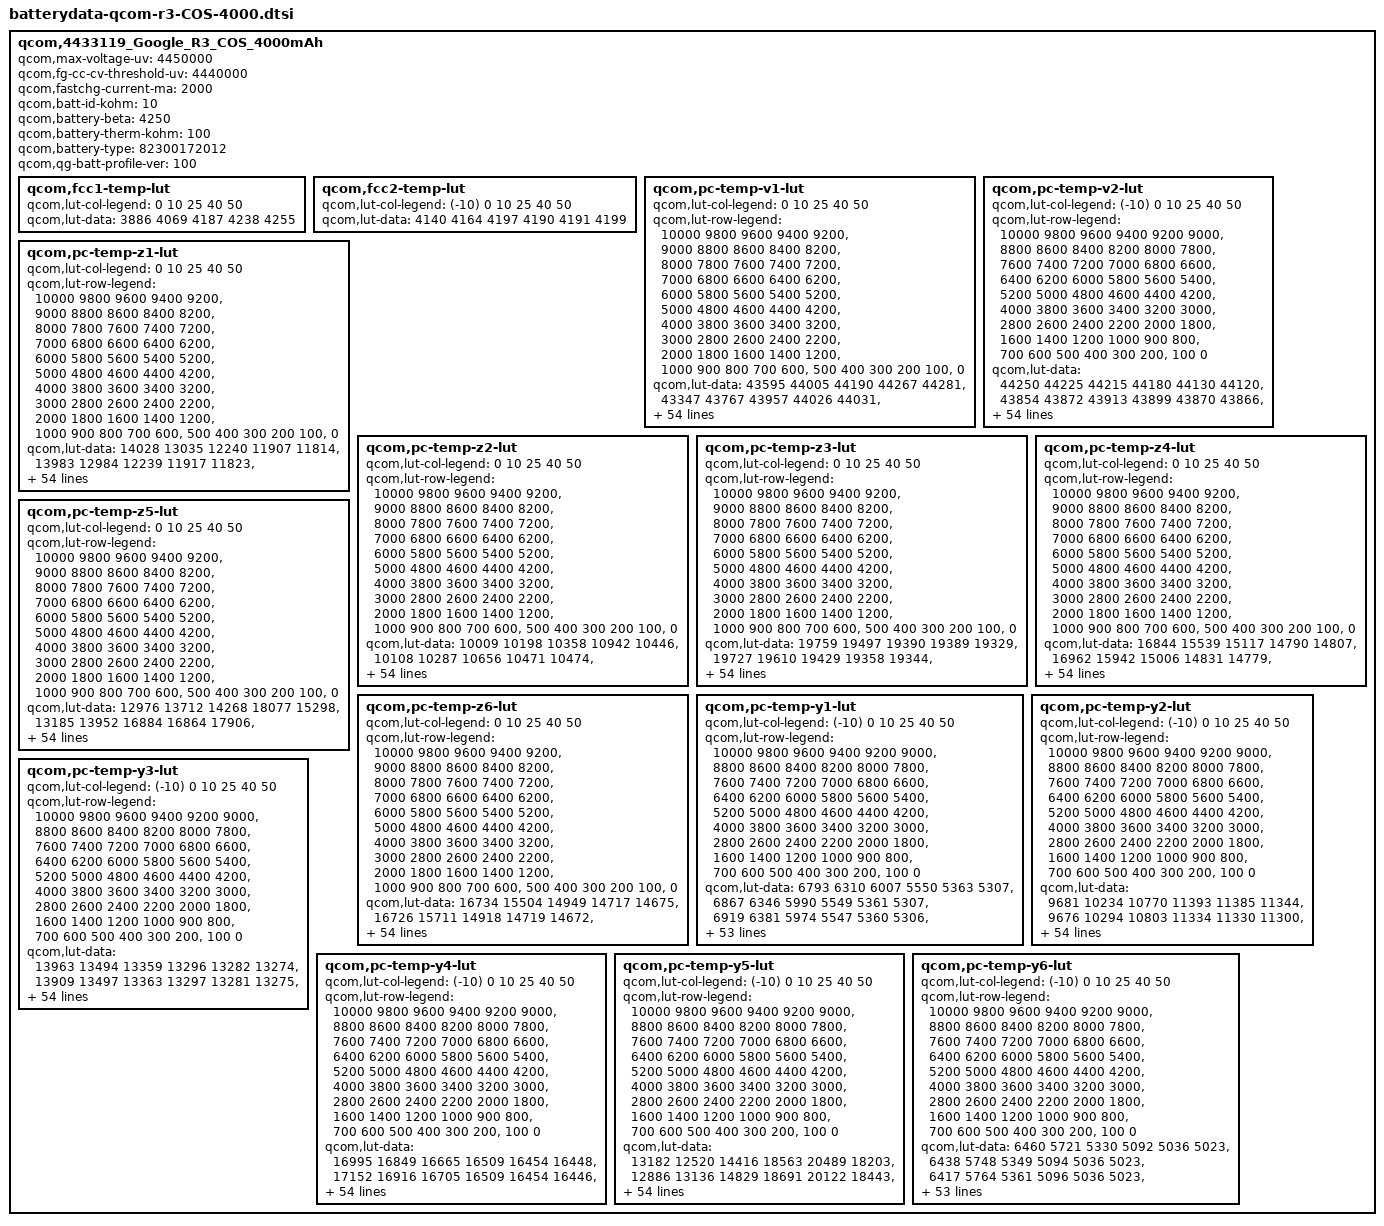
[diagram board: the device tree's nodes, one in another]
// SPDX-License-Identifier: GPL-2.0
qcom,4433119_Google_R3_COS_4000mAh {
	/* 4433119_Google_R3_COS_4000mAh_Feb5th2020 */
	qcom,max-voltage-uv = <4450000>;
	qcom,fg-cc-cv-threshold-uv = <4440000>;
	qcom,fastchg-current-ma = <2000>;
	qcom,batt-id-kohm = <10>;
	qcom,battery-beta = <4250>;
	qcom,battery-therm-kohm = <100>;
	qcom,battery-type = "82300172012";
	qcom,qg-batt-profile-ver = <100>;

	qcom,fcc1-temp-lut {
		qcom,lut-col-legend = <0 10 25 40 50>;
		qcom,lut-data = <3886 4069 4187 4238 4255>;
	};

	qcom,fcc2-temp-lut {
		qcom,lut-col-legend = <(-10) 0 10 25 40 50>;
		qcom,lut-data = <4140 4164 4197 4190 4191 4199>;
	};

	qcom,pc-temp-v1-lut {
		qcom,lut-col-legend = <0 10 25 40 50>;
		qcom,lut-row-legend = <10000 9800 9600 9400 9200>,
			<9000 8800 8600 8400 8200>,
			<8000 7800 7600 7400 7200>,
			<7000 6800 6600 6400 6200>,
			<6000 5800 5600 5400 5200>,
			<5000 4800 4600 4400 4200>,
			<4000 3800 3600 3400 3200>,
			<3000 2800 2600 2400 2200>,
			<2000 1800 1600 1400 1200>,
			<1000 900 800 700 600>,
			<500 400 300 200 100>,
			<0>;
		qcom,lut-data = <43595 44005 44190 44267 44281>,
			<43347 43767 43957 44026 44031>,
			<43101 43540 43748 43802 43812>,
			<42858 43315 43511 43591 43597>,
			<42618 43080 43286 43368 43378>,
			<42378 42836 43053 43136 43156>,
			<42144 42592 42813 42900 42923>,
			<41914 42349 42569 42659 42681>,
			<41689 42106 42322 42415 42438>,
			<41469 41870 42074 42168 42191>,
			<41255 41638 41833 41924 41947>,
			<41046 41412 41598 41685 41708>,
			<40842 41189 41369 41452 41474>,
			<40644 40974 41146 41222 41243>,
			<40451 40765 40928 40998 41016>,
			<40264 40564 40719 40782 40798>,
			<40085 40370 40515 40573 40588>,
			<39921 40182 40321 40373 40385>,
			<39770 40003 40135 40185 40196>,
			<39627 39837 39956 40004 40014>,
			<39491 39679 39793 39824 39832>,
			<39361 39524 39626 39649 39652>,
			<39236 39374 39392 39451 39458>,
			<39115 39213 39090 39199 39220>,
			<39000 39012 38890 38978 38998>,
			<38891 38806 38785 38837 38847>,
			<38788 38656 38701 38725 38725>,
			<38690 38535 38612 38617 38613>,
			<38597 38446 38527 38515 38509>,
			<38508 38385 38447 38422 38414>,
			<38433 38337 38373 38337 38326>,
			<38363 38293 38304 38262 38246>,
			<38306 38254 38243 38195 38175>,
			<38259 38218 38187 38135 38110>,
			<38220 38186 38140 38080 38047>,
			<38181 38153 38099 38031 37988>,
			<38147 38118 38055 37977 37925>,
			<38107 38079 38010 37920 37856>,
			<38054 38025 37954 37853 37780>,
			<37985 37934 37869 37768 37693>,
			<37897 37821 37757 37664 37592>,
			<37763 37703 37633 37547 37478>,
			<37624 37569 37492 37411 37342>,
			<37492 37405 37333 37255 37187>,
			<37360 37258 37180 37101 37036>,
			<37246 37156 37088 37012 36954>,
			<37203 37128 37062 36991 36931>,
			<37162 37106 37047 36977 36915>,
			<37124 37077 37030 36960 36901>,
			<37072 37036 36993 36923 36858>,
			<36898 36858 36800 36720 36634>,
			<36470 36434 36383 36297 36201>,
			<35892 35855 35812 35731 35633>,
			<35104 35063 35035 34962 34862>,
			<33798 33784 33845 33793 33676>,
			<30000 30000 30000 30000 30000>;
	};

	qcom,pc-temp-v2-lut {
		qcom,lut-col-legend = <(-10) 0 10 25 40 50>;
		qcom,lut-row-legend = <10000 9800 9600 9400 9200 9000>,
			<8800 8600 8400 8200 8000 7800>,
			<7600 7400 7200 7000 6800 6600>,
			<6400 6200 6000 5800 5600 5400>,
			<5200 5000 4800 4600 4400 4200>,
			<4000 3800 3600 3400 3200 3000>,
			<2800 2600 2400 2200 2000 1800>,
			<1600 1400 1200 1000 900 800>,
			<700 600 500 400 300 200>,
			<100 0>;
		qcom,lut-data = <44250 44225 44215 44180 44130 44120>,
			<43854 43872 43913 43899 43870 43866>,
			<43497 43554 43634 43636 43621 43622>,
			<43184 43278 43380 43394 43386 43389>,
			<42908 43038 43150 43170 43164 43168>,
			<42649 42795 42913 42940 42935 42940>,
			<42410 42538 42663 42698 42696 42702>,
			<42172 42281 42412 42454 42454 42461>,
			<41906 42034 42164 42211 42213 42220>,
			<41625 41792 41919 41969 41972 41979>,
			<41376 41547 41679 41731 41734 41742>,
			<41163 41295 41443 41496 41499 41509>,
			<40954 41060 41215 41267 41270 41280>,
			<40735 40865 40997 41042 41044 41055>,
			<40509 40680 40785 40823 40825 40835>,
			<40253 40457 40581 40610 40614 40623>,
			<39958 40199 40382 40404 40411 40417>,
			<39698 39950 40166 40207 40215 40220>,
			<39500 39718 39922 40026 40029 40033>,
			<39321 39496 39680 39839 39843 39849>,
			<39137 39288 39450 39621 39651 39664>,
			<38954 39091 39231 39390 39452 39474>,
			<38764 38909 39039 39171 39237 39259>,
			<38547 38742 38866 38959 38998 39014>,
			<38364 38574 38711 38780 38803 38818>,
			<38260 38378 38572 38640 38665 38678>,
			<38183 38196 38445 38519 38549 38560>,
			<38111 38097 38326 38408 38440 38450>,
			<38044 38034 38213 38309 38341 38351>,
			<37980 37980 38104 38217 38250 38257>,
			<37919 37930 37994 38132 38167 38171>,
			<37857 37883 37910 38054 38091 38091>,
			<37795 37836 37858 37984 38023 38022>,
			<37731 37788 37816 37919 37958 37955>,
			<37667 37738 37774 37852 37886 37878>,
			<37603 37686 37735 37783 37810 37793>,
			<37537 37629 37691 37715 37725 37699>,
			<37470 37568 37639 37649 37627 37586>,
			<37401 37500 37576 37580 37527 37477>,
			<37332 37421 37495 37503 37442 37387>,
			<37262 37328 37396 37416 37358 37302>,
			<37193 37217 37286 37314 37263 37210>,
			<37124 37093 37153 37189 37145 37091>,
			<37045 36977 36998 37048 37015 36958>,
			<36956 36870 36857 36896 36867 36817>,
			<36849 36780 36758 36848 36833 36785>,
			<36791 36741 36724 36830 36824 36776>,
			<36720 36704 36691 36813 36809 36763>,
			<36650 36664 36644 36786 36786 36739>,
			<36543 36598 36569 36723 36726 36672>,
			<36383 36439 36389 36494 36486 36401>,
			<36111 36051 35987 36019 36013 35922>,
			<35674 35418 35358 35384 35388 35292>,
			<34955 34428 34451 34506 34528 34423>,
			<33712 32850 33003 33173 33262 33124>,
			<30996 29589 29511 29509 29575 29508>;
	};

	qcom,pc-temp-z1-lut {
		qcom,lut-col-legend = <0 10 25 40 50>;
		qcom,lut-row-legend = <10000 9800 9600 9400 9200>,
			<9000 8800 8600 8400 8200>,
			<8000 7800 7600 7400 7200>,
			<7000 6800 6600 6400 6200>,
			<6000 5800 5600 5400 5200>,
			<5000 4800 4600 4400 4200>,
			<4000 3800 3600 3400 3200>,
			<3000 2800 2600 2400 2200>,
			<2000 1800 1600 1400 1200>,
			<1000 900 800 700 600>,
			<500 400 300 200 100>,
			<0>;
		qcom,lut-data = <14028 13035 12240 11907 11814>,
			<13983 12984 12239 11917 11823>,
			<13967 12988 12232 11912 11821>,
			<13958 12998 12222 11903 11815>,
			<13957 12996 12216 11896 11812>,
			<13970 12991 12210 11890 11810>,
			<13985 12985 12200 11886 11808>,
			<13987 12976 12192 11883 11807>,
			<13971 12964 12186 11880 11806>,
			<13961 12949 12181 11878 11805>,
			<13918 12932 12181 11876 11804>,
			<13864 12921 12185 11875 11803>,
			<13846 12913 12186 11874 11803>,
			<13819 12909 12181 11873 11802>,
			<13796 12911 12175 11873 11802>,
			<13762 12914 12174 11873 11802>,
			<13718 12915 12173 11874 11803>,
			<13703 12912 12174 11874 11803>,
			<13702 12910 12181 11875 11804>,
			<13702 12918 12186 11876 11806>,
			<13698 12933 12188 11878 11807>,
			<13693 12945 12189 11879 11807>,
			<13696 12958 12191 11881 11808>,
			<13711 12965 12194 11883 11810>,
			<13726 12960 12197 11886 11813>,
			<13729 12954 12203 11889 11816>,
			<13728 12954 12209 11893 11819>,
			<13729 12961 12214 11897 11821>,
			<13735 12970 12220 11901 11824>,
			<13745 12986 12225 11904 11827>,
			<13763 13003 12232 11907 11829>,
			<13803 13012 12236 11910 11831>,
			<13826 13021 12239 11914 11834>,
			<13818 13026 12243 11917 11836>,
			<13803 13037 12249 11920 11839>,
			<13794 13050 12260 11925 11842>,
			<13790 13056 12268 11929 11845>,
			<13793 13060 12276 11933 11848>,
			<13807 13066 12283 11937 11852>,
			<13830 13085 12288 11941 11855>,
			<13847 13103 12292 11946 11857>,
			<13861 13112 12298 11949 11860>,
			<13866 13121 12306 11952 11863>,
			<13850 13131 12312 11955 11865>,
			<13851 13131 12319 11959 11867>,
			<13941 13123 12323 11964 11869>,
			<13890 13128 12319 11964 11868>,
			<13883 13157 12328 11965 11869>,
			<13860 13139 12334 11967 11870>,
			<13916 13146 12332 11971 11874>,
			<13922 13151 12347 11976 11878>,
			<13891 13186 12360 11982 11884>,
			<13965 13208 12371 11994 11892>,
			<13967 13229 12405 12008 11902>,
			<13967 13229 12405 12008 11902>,
			<13967 13229 12405 12008 11902>;
	};

	qcom,pc-temp-z2-lut {
		qcom,lut-col-legend = <0 10 25 40 50>;
		qcom,lut-row-legend = <10000 9800 9600 9400 9200>,
			<9000 8800 8600 8400 8200>,
			<8000 7800 7600 7400 7200>,
			<7000 6800 6600 6400 6200>,
			<6000 5800 5600 5400 5200>,
			<5000 4800 4600 4400 4200>,
			<4000 3800 3600 3400 3200>,
			<3000 2800 2600 2400 2200>,
			<2000 1800 1600 1400 1200>,
			<1000 900 800 700 600>,
			<500 400 300 200 100>,
			<0>;
		qcom,lut-data = <10009 10198 10358 10942 10446>,
			<10108 10287 10656 10471 10474>,
			<10101 10273 11089 10519 10509>,
			<10080 10251 10496 10590 10515>,
			<10072 10229 10444 10578 10457>,
			<10071 10202 10430 10557 10387>,
			<10071 10189 10560 10514 10366>,
			<10071 10185 10673 10442 10355>,
			<10070 10182 10563 10415 10353>,
			<10067 10173 10369 10407 10362>,
			<10061 10156 10339 10404 10374>,
			<10052 10145 10362 10395 10384>,
			<10044 10139 10394 10390 10394>,
			<10031 10136 10550 10403 10406>,
			<10019 10135 10729 10425 10420>,
			<10009 10136 10784 10436 10433>,
			<10000 10141 10818 10441 10444>,
			<9995 10152 10809 10447 10456>,
			<9992 10168 10628 10467 10477>,
			<9990 10192 10501 10490 10502>,
			<9989 10224 10519 10497 10517>,
			<9987 10253 10542 10500 10530>,
			<9987 10280 10551 10500 10542>,
			<9990 10306 10556 10492 10567>,
			<9995 10338 10554 10486 10588>,
			<10001 10367 10507 10561 10569>,
			<10012 10373 10464 10685 10519>,
			<10026 10371 10497 10677 10478>,
			<10047 10370 10563 10566 10407>,
			<10071 10378 10575 10509 10374>,
			<10090 10386 10560 10500 10378>,
			<10108 10390 10551 10496 10386>,
			<10120 10391 10561 10502 10411>,
			<10127 10394 10579 10516 10466>,
			<10131 10402 10602 10537 10522>,
			<10134 10413 10637 10579 10586>,
			<10130 10420 10657 10630 10635>,
			<10128 10427 10663 10702 10663>,
			<10134 10438 10671 10765 10686>,
			<10142 10467 10700 10793 10707>,
			<10154 10490 10739 10811 10726>,
			<10179 10486 10745 10815 10743>,
			<10175 10477 10743 10804 10757>,
			<9868 10484 10742 10808 10759>,
			<9608 10548 10759 10817 10756>,
			<9548 10647 10815 10794 10794>,
			<9578 10593 10799 10791 10780>,
			<9565 10546 10776 10785 10782>,
			<9596 10591 10771 10803 10821>,
			<9648 10624 10789 10884 10958>,
			<9609 10551 10859 10843 10768>,
			<9499 10497 10844 10729 10584>,
			<9431 10306 10803 10645 10503>,
			<9301 10127 10753 10558 10480>,
			<9301 10127 10753 10558 10480>,
			<9301 10127 10753 10558 10480>;
	};

	qcom,pc-temp-z3-lut {
		qcom,lut-col-legend = <0 10 25 40 50>;
		qcom,lut-row-legend = <10000 9800 9600 9400 9200>,
			<9000 8800 8600 8400 8200>,
			<8000 7800 7600 7400 7200>,
			<7000 6800 6600 6400 6200>,
			<6000 5800 5600 5400 5200>,
			<5000 4800 4600 4400 4200>,
			<4000 3800 3600 3400 3200>,
			<3000 2800 2600 2400 2200>,
			<2000 1800 1600 1400 1200>,
			<1000 900 800 700 600>,
			<500 400 300 200 100>,
			<0>;
		qcom,lut-data = <19759 19497 19390 19389 19329>,
			<19727 19610 19429 19358 19344>,
			<19708 19640 19436 19369 19343>,
			<19693 19652 19477 19392 19365>,
			<19689 19653 19480 19400 19367>,
			<19695 19649 19482 19403 19367>,
			<19704 19645 19487 19401 19367>,
			<19711 19638 19490 19394 19367>,
			<19718 19631 19480 19388 19366>,
			<19723 19623 19462 19384 19364>,
			<19726 19612 19450 19379 19361>,
			<19728 19603 19440 19372 19355>,
			<19729 19595 19436 19365 19350>,
			<19729 19588 19441 19363 19348>,
			<19727 19578 19448 19362 19347>,
			<19723 19566 19446 19360 19346>,
			<19717 19557 19442 19359 19344>,
			<19709 19550 19436 19358 19341>,
			<19699 19544 19424 19356 19338>,
			<19689 19538 19415 19355 19336>,
			<19682 19534 19414 19356 19336>,
			<19675 19532 19414 19358 19338>,
			<19674 19531 19418 19359 19339>,
			<19677 19530 19431 19353 19334>,
			<19682 19541 19435 19349 19330>,
			<19686 19558 19422 19357 19342>,
			<19691 19560 19409 19371 19367>,
			<19695 19558 19411 19380 19371>,
			<19701 19554 19416 19386 19368>,
			<19705 19550 19421 19388 19364>,
			<19706 19545 19430 19384 19359>,
			<19705 19540 19435 19377 19353>,
			<19702 19536 19433 19372 19349>,
			<19697 19532 19430 19367 19344>,
			<19690 19529 19427 19363 19341>,
			<19682 19526 19422 19359 19338>,
			<19672 19523 19418 19357 19337>,
			<19660 19519 19416 19357 19337>,
			<19646 19516 19414 19358 19337>,
			<19631 19514 19411 19357 19337>,
			<19622 19511 19408 19355 19337>,
			<19619 19507 19406 19353 19336>,
			<19603 19500 19405 19351 19334>,
			<19458 19494 19403 19351 19335>,
			<19310 19471 19396 19350 19337>,
			<19271 19440 19380 19339 19323>,
			<19269 19404 19378 19337 19322>,
			<19269 19347 19365 19333 19321>,
			<19269 19334 19357 19332 19315>,
			<19267 19322 19359 19328 19308>,
			<19268 19333 19350 19333 19325>,
			<19271 19333 19346 19340 19336>,
			<19273 19335 19340 19344 19337>,
			<19292 19337 19333 19343 19329>,
			<19292 19337 19333 19343 19329>,
			<19292 19337 19333 19343 19329>;
	};

	qcom,pc-temp-z4-lut {
		qcom,lut-col-legend = <0 10 25 40 50>;
		qcom,lut-row-legend = <10000 9800 9600 9400 9200>,
			<9000 8800 8600 8400 8200>,
			<8000 7800 7600 7400 7200>,
			<7000 6800 6600 6400 6200>,
			<6000 5800 5600 5400 5200>,
			<5000 4800 4600 4400 4200>,
			<4000 3800 3600 3400 3200>,
			<3000 2800 2600 2400 2200>,
			<2000 1800 1600 1400 1200>,
			<1000 900 800 700 600>,
			<500 400 300 200 100>,
			<0>;
		qcom,lut-data = <16844 15539 15117 14790 14807>,
			<16962 15942 15006 14831 14779>,
			<16817 15764 14981 14784 14746>,
			<16455 15492 15054 14853 14796>,
			<16163 15332 14958 14823 14790>,
			<15949 15213 14880 14783 14766>,
			<15766 15119 14815 14760 14747>,
			<15619 15042 14773 14743 14729>,
			<15495 14980 14757 14729 14716>,
			<15393 14931 14745 14715 14706>,
			<15306 14890 14739 14706 14698>,
			<15233 14854 14732 14701 14693>,
			<15173 14818 14723 14697 14688>,
			<15121 14792 14701 14691 14682>,
			<15078 14782 14680 14684 14674>,
			<15043 14777 14675 14678 14668>,
			<15013 14771 14672 14673 14664>,
			<14985 14764 14671 14669 14661>,
			<14958 14757 14682 14665 14658>,
			<14936 14749 14690 14663 14656>,
			<14921 14740 14691 14664 14657>,
			<14909 14738 14692 14669 14663>,
			<14896 14738 14721 14683 14677>,
			<14883 14739 14817 14756 14734>,
			<14870 14767 14856 14812 14786>,
			<14858 14813 14847 14795 14769>,
			<14847 14834 14833 14760 14725>,
			<14838 14850 14813 14732 14703>,
			<14831 14857 14787 14708 14692>,
			<14825 14846 14764 14693 14684>,
			<14823 14828 14740 14687 14677>,
			<14821 14814 14726 14683 14672>,
			<14820 14801 14721 14680 14667>,
			<14816 14789 14718 14678 14663>,
			<14810 14777 14717 14678 14663>,
			<14804 14767 14717 14679 14666>,
			<14796 14758 14717 14681 14670>,
			<14788 14750 14718 14685 14677>,
			<14779 14748 14719 14688 14683>,
			<14770 14750 14721 14692 14684>,
			<14762 14752 14725 14695 14683>,
			<14756 14747 14723 14694 14682>,
			<14760 14734 14715 14687 14676>,
			<14885 14726 14708 14685 14676>,
			<14949 14706 14697 14685 14679>,
			<14961 14680 14664 14660 14659>,
			<14954 14709 14655 14652 14650>,
			<14949 14762 14656 14641 14636>,
			<14946 14770 14653 14628 14628>,
			<14937 14776 14648 14629 14630>,
			<14933 14768 14671 14643 14633>,
			<14959 14787 14681 14643 14632>,
			<14983 14798 14689 14639 14632>,
			<15013 14819 14699 14640 14638>,
			<15013 14819 14699 14640 14638>,
			<15013 14819 14699 14640 14638>;
	};

	qcom,pc-temp-z5-lut {
		qcom,lut-col-legend = <0 10 25 40 50>;
		qcom,lut-row-legend = <10000 9800 9600 9400 9200>,
			<9000 8800 8600 8400 8200>,
			<8000 7800 7600 7400 7200>,
			<7000 6800 6600 6400 6200>,
			<6000 5800 5600 5400 5200>,
			<5000 4800 4600 4400 4200>,
			<4000 3800 3600 3400 3200>,
			<3000 2800 2600 2400 2200>,
			<2000 1800 1600 1400 1200>,
			<1000 900 800 700 600>,
			<500 400 300 200 100>,
			<0>;
		qcom,lut-data = <12976 13712 14268 18077 15298>,
			<13185 13952 16884 16864 17906>,
			<13555 14248 16307 19571 18865>,
			<14096 14742 16975 18252 19328>,
			<14635 15126 17533 19234 19286>,
			<15174 15481 18230 20301 19299>,
			<15720 15891 19545 20197 19472>,
			<16255 16453 20570 19777 19982>,
			<16787 17054 20811 19763 20546>,
			<17273 17550 20851 20491 21275>,
			<17706 18025 20772 20939 21723>,
			<18101 18707 20697 20438 21468>,
			<18480 20060 20745 19832 21031>,
			<18880 21133 23966 20001 21213>,
			<19163 21295 27961 20762 22364>,
			<19310 21367 29218 21538 23324>,
			<19412 21525 29991 22335 23978>,
			<19466 21982 30046 23141 24478>,
			<19450 22655 27297 23900 24795>,
			<19425 23665 25562 24757 25010>,
			<19443 25119 26623 26188 25319>,
			<19541 26704 28445 28219 26865>,
			<19823 28426 32117 28530 27381>,
			<20743 31011 39033 24063 22340>,
			<22079 39631 41155 20072 17295>,
			<23581 49982 32006 19364 17815>,
			<25484 50890 23232 18954 19595>,
			<27511 47262 22241 19509 20975>,
			<30286 43513 21901 22295 22134>,
			<33142 40398 22529 24707 23156>,
			<34952 37759 25805 26214 24090>,
			<36503 36163 29256 27538 25038>,
			<37208 34823 32267 28961 26145>,
			<36842 34368 34607 30263 27396>,
			<36095 34602 35384 30894 28532>,
			<35412 34964 35868 31248 29760>,
			<34345 35262 35956 31443 30309>,
			<33274 35612 35497 31636 29860>,
			<32344 36165 34796 31773 29037>,
			<31409 37855 33441 30782 28037>,
			<31324 39251 31824 28279 26649>,
			<33708 38151 31700 27136 25688>,
			<34203 35924 32204 26599 25029>,
			<22454 35428 31573 26088 24602>,
			<13540 33715 30949 25422 24161>,
			<11472 29995 32564 25808 21848>,
			<11396 22046 32105 25722 22502>,
			<11378 14305 26237 26171 25462>,
			<11335 13409 23342 30243 26130>,
			<11287 12996 24703 28550 22034>,
			<11313 13553 19901 22988 25021>,
			<11382 13212 17308 22778 26971>,
			<11308 12944 15958 23549 25921>,
			<11404 12612 14737 22098 20263>,
			<11404 12612 14737 22098 20263>,
			<11404 12612 14737 22098 20263>;
	};

	qcom,pc-temp-z6-lut {
		qcom,lut-col-legend = <0 10 25 40 50>;
		qcom,lut-row-legend = <10000 9800 9600 9400 9200>,
			<9000 8800 8600 8400 8200>,
			<8000 7800 7600 7400 7200>,
			<7000 6800 6600 6400 6200>,
			<6000 5800 5600 5400 5200>,
			<5000 4800 4600 4400 4200>,
			<4000 3800 3600 3400 3200>,
			<3000 2800 2600 2400 2200>,
			<2000 1800 1600 1400 1200>,
			<1000 900 800 700 600>,
			<500 400 300 200 100>,
			<0>;
		qcom,lut-data = <16734 15504 14949 14717 14675>,
			<16726 15711 14918 14719 14672>,
			<16627 15630 14906 14703 14657>,
			<16428 15503 14953 14743 14690>,
			<16273 15419 14909 14733 14688>,
			<16163 15352 14874 14718 14677>,
			<16070 15296 14848 14706 14669>,
			<15994 15250 14826 14695 14662>,
			<15929 15210 14808 14685 14656>,
			<15873 15175 14793 14676 14650>,
			<15825 15145 14782 14669 14644>,
			<15781 15119 14774 14663 14639>,
			<15742 15095 14767 14657 14634>,
			<15705 15077 14761 14653 14630>,
			<15671 15067 14755 14649 14626>,
			<15640 15059 14751 14646 14622>,
			<15612 15052 14747 14643 14619>,
			<15585 15046 14745 14640 14616>,
			<15557 15041 14743 14638 14614>,
			<15538 15037 14742 14637 14612>,
			<15530 15033 14742 14637 14612>,
			<15524 15033 14743 14641 14616>,
			<15523 15034 14759 14648 14623>,
			<15524 15037 14808 14678 14646>,
			<15526 15057 14827 14700 14667>,
			<15528 15086 14819 14697 14666>,
			<15530 15099 14808 14691 14661>,
			<15532 15107 14800 14685 14656>,
			<15537 15110 14794 14679 14649>,
			<15542 15106 14789 14673 14644>,
			<15546 15098 14784 14668 14638>,
			<15549 15092 14781 14664 14633>,
			<15551 15088 14779 14660 14628>,
			<15552 15084 14778 14656 14624>,
			<15552 15081 14777 14655 14623>,
			<15552 15078 14775 14654 14623>,
			<15551 15078 14775 14653 14623>,
			<15550 15079 14776 14656 14626>,
			<15549 15080 14778 14658 14630>,
			<15546 15086 14779 14660 14630>,
			<15546 15092 14781 14661 14630>,
			<15551 15091 14781 14660 14630>,
			<15553 15088 14780 14657 14627>,
			<15543 15086 14778 14656 14627>,
			<15514 15076 14773 14657 14630>,
			<15506 15058 14753 14641 14614>,
			<15504 15055 14749 14637 14610>,
			<15505 15049 14744 14629 14604>,
			<15506 15048 14739 14624 14596>,
			<15510 15050 14740 14623 14595>,
			<15521 15062 14749 14632 14606>,
			<15547 15079 14756 14638 14612>,
			<15580 15100 14763 14641 14615>,
			<15623 15133 14772 14645 14617>,
			<15623 15133 14772 14645 14617>,
			<15623 15133 14772 14645 14617>;
	};

	qcom,pc-temp-y1-lut {
		qcom,lut-col-legend = <(-10) 0 10 25 40 50>;
		qcom,lut-row-legend = <10000 9800 9600 9400 9200 9000>,
			<8800 8600 8400 8200 8000 7800>,
			<7600 7400 7200 7000 6800 6600>,
			<6400 6200 6000 5800 5600 5400>,
			<5200 5000 4800 4600 4400 4200>,
			<4000 3800 3600 3400 3200 3000>,
			<2800 2600 2400 2200 2000 1800>,
			<1600 1400 1200 1000 900 800>,
			<700 600 500 400 300 200>,
			<100 0>;
		qcom,lut-data = <6793 6310 6007 5550 5363 5307>,
			<6867 6346 5990 5549 5361 5307>,
			<6919 6381 5974 5547 5360 5306>,
			<6952 6411 5961 5544 5358 5305>,
			<6970 6430 5953 5543 5356 5304>,
			<6977 6435 5951 5542 5354 5303>,
			<6959 6425 5955 5542 5353 5302>,
			<6938 6415 5960 5542 5351 5301>,
			<6943 6426 5962 5539 5350 5300>,
			<6960 6450 5965 5533 5348 5299>,
			<6964 6455 5965 5531 5347 5298>,
			<6959 6440 5961 5532 5346 5297>,
			<6955 6426 5958 5533 5345 5297>,
			<6947 6423 5956 5532 5344 5297>,
			<6933 6423 5954 5531 5344 5296>,
			<6939 6423 5955 5531 5343 5296>,
			<6981 6421 5959 5531 5343 5296>,
			<7004 6421 5961 5532 5343 5296>,
			<6975 6426 5970 5534 5343 5296>,
			<6938 6432 5977 5536 5343 5296>,
			<6940 6433 5974 5536 5344 5297>,
			<6961 6434 5969 5535 5345 5297>,
			<6968 6434 5969 5535 5345 5298>,
			<6953 6430 5974 5537 5346 5298>,
			<6938 6429 5977 5539 5347 5299>,
			<6935 6443 5982 5544 5348 5300>,
			<6934 6459 5986 5549 5349 5301>,
			<6933 6460 5986 5552 5351 5302>,
			<6933 6459 5986 5554 5353 5303>,
			<6933 6461 5987 5556 5355 5304>,
			<6933 6451 5991 5559 5357 5305>,
			<6935 6438 5993 5561 5359 5306>,
			<6942 6431 5987 5562 5361 5308>,
			<6962 6426 5979 5562 5363 5310>,
			<6971 6425 5981 5563 5366 5312>,
			<6963 6431 5987 5569 5369 5313>,
			<6955 6434 5989 5572 5371 5314>,
			<6951 6430 5986 5574 5372 5316>,
			<6941 6425 5983 5575 5374 5317>,
			<6939 6429 5988 5577 5375 5319>,
			<6959 6441 5997 5582 5377 5320>,
			<6964 6450 5997 5585 5379 5321>,
			<6942 6453 5999 5589 5380 5322>,
			<7006 6463 6010 5590 5383 5325>,
			<7058 6472 6020 5594 5386 5327>,
			<7031 6464 6017 5599 5389 5329>,
			<7052 6476 6024 5602 5390 5329>,
			<7033 6481 6019 5608 5391 5329>,
			<7136 6501 6027 5609 5392 5330>,
			<7150 6516 6038 5619 5392 5330>,
			<7259 6527 6040 5623 5392 5330>,
			<7339 6582 6060 5623 5398 5335>,
			<7406 6679 6084 5639 5405 5340>,
			<7517 6750 6131 5676 5415 5346>,
			<7517 6750 6131 5676 5415 5346>,
			<7517 6750 6131 5676 5415 5346>;
	};

	qcom,pc-temp-y2-lut {
		qcom,lut-col-legend = <(-10) 0 10 25 40 50>;
		qcom,lut-row-legend = <10000 9800 9600 9400 9200 9000>,
			<8800 8600 8400 8200 8000 7800>,
			<7600 7400 7200 7000 6800 6600>,
			<6400 6200 6000 5800 5600 5400>,
			<5200 5000 4800 4600 4400 4200>,
			<4000 3800 3600 3400 3200 3000>,
			<2800 2600 2400 2200 2000 1800>,
			<1600 1400 1200 1000 900 800>,
			<700 600 500 400 300 200>,
			<100 0>;
		qcom,lut-data = <9681 10234 10770 11393 11385 11344>,
			<9676 10294 10803 11334 11330 11300>,
			<9675 10359 10828 11277 11275 11256>,
			<9677 10421 10845 11223 11222 11216>,
			<9682 10472 10854 11172 11172 11179>,
			<9694 10504 10855 11126 11129 11148>,
			<9849 10525 10840 11077 11085 11117>,
			<10007 10539 10822 11041 11051 11095>,
			<9938 10552 10816 11027 11034 11082>,
			<9749 10573 10813 11017 11023 11067>,
			<9689 10611 10815 11009 11014 11048>,
			<9688 10728 10823 10997 11012 11002>,
			<9686 10822 10837 10992 11013 10975>,
			<9684 10850 10889 10998 11008 10975>,
			<9682 10872 10969 11012 11006 10980>,
			<9680 10909 11048 11034 11030 10989>,
			<9677 10962 11132 11074 11087 11007>,
			<9674 10996 11164 11126 11143 11022>,
			<9673 11013 11172 11210 11193 11033>,
			<9672 11023 11175 11278 11249 11050>,
			<9671 11025 11178 11306 11348 11217>,
			<9671 11005 11185 11326 11454 11467>,
			<9670 10927 11194 11338 11450 11480>,
			<9669 10570 11211 11348 11353 11377>,
			<9667 10252 11230 11361 11305 11331>,
			<9667 10000 11253 11386 11341 11349>,
			<9666 9742 11269 11420 11394 11373>,
			<9665 9700 11237 11453 11433 11397>,
			<9664 9692 11160 11489 11468 11439>,
			<9664 9685 11138 11510 11501 11479>,
			<9663 9680 11138 11526 11532 11523>,
			<9663 9675 11137 11540 11566 11558>,
			<9663 9671 11111 11553 11630 11580>,
			<9662 9668 11061 11564 11693 11598>,
			<9662 9666 11015 11554 11695 11612>,
			<9662 9664 10966 11509 11668 11629>,
			<9662 9663 10890 11473 11639 11634>,
			<9662 9662 10677 11455 11604 11615>,
			<9661 9661 10428 11436 11572 11588>,
			<9661 9661 10170 11410 11547 11558>,
			<9661 9660 9912 11376 11528 11532>,
			<9661 9660 9756 11332 11549 11522>,
			<9661 9660 9708 11300 11519 11494>,
			<9660 9659 9716 11320 11509 11566>,
			<9660 9659 9686 11210 11549 11552>,
			<9659 9658 9672 11159 11393 11325>,
			<9658 9658 9667 11122 11354 11267>,
			<9656 9657 9664 11102 11325 11205>,
			<9655 9657 9661 11071 11328 11198>,
			<9653 9656 9659 11051 11341 11205>,
			<9652 9654 9657 10980 11318 11209>,
			<9651 9651 9656 10834 11201 11151>,
			<9650 9650 9653 10710 11113 11025>,
			<9648 9648 9651 10543 11022 10921>,
			<9648 9648 9651 10543 11022 10921>,
			<9648 9648 9651 10543 11022 10921>;
	};

	qcom,pc-temp-y3-lut {
		qcom,lut-col-legend = <(-10) 0 10 25 40 50>;
		qcom,lut-row-legend = <10000 9800 9600 9400 9200 9000>,
			<8800 8600 8400 8200 8000 7800>,
			<7600 7400 7200 7000 6800 6600>,
			<6400 6200 6000 5800 5600 5400>,
			<5200 5000 4800 4600 4400 4200>,
			<4000 3800 3600 3400 3200 3000>,
			<2800 2600 2400 2200 2000 1800>,
			<1600 1400 1200 1000 900 800>,
			<700 600 500 400 300 200>,
			<100 0>;
		qcom,lut-data = <13963 13494 13359 13296 13282 13274>,
			<13909 13497 13363 13297 13281 13275>,
			<13856 13499 13368 13299 13281 13275>,
			<13806 13501 13372 13301 13282 13276>,
			<13761 13502 13376 13303 13282 13276>,
			<13726 13502 13378 13304 13283 13277>,
			<13695 13500 13379 13304 13284 13277>,
			<13671 13497 13380 13304 13285 13277>,
			<13653 13495 13380 13305 13286 13278>,
			<13634 13492 13381 13305 13287 13278>,
			<13617 13486 13380 13306 13287 13280>,
			<13598 13466 13378 13307 13288 13282>,
			<13586 13450 13375 13308 13288 13284>,
			<13588 13443 13373 13309 13288 13285>,
			<13590 13438 13371 13309 13288 13285>,
			<13585 13433 13369 13309 13289 13285>,
			<13560 13427 13367 13308 13292 13284>,
			<13545 13419 13364 13308 13293 13284>,
			<13544 13405 13359 13309 13292 13285>,
			<13545 13390 13352 13309 13292 13285>,
			<13548 13377 13344 13308 13291 13286>,
			<13556 13367 13337 13306 13291 13286>,
			<13558 13362 13333 13302 13289 13285>,
			<13545 13367 13330 13298 13283 13280>,
			<13533 13371 13327 13295 13280 13277>,
			<13542 13364 13324 13293 13280 13276>,
			<13569 13353 13322 13292 13279 13276>,
			<13597 13353 13319 13292 13279 13276>,
			<13628 13361 13317 13292 13279 13276>,
			<13663 13372 13315 13292 13279 13276>,
			<13700 13396 13315 13292 13279 13275>,
			<13740 13429 13314 13292 13279 13274>,
			<13776 13463 13316 13292 13280 13275>,
			<13810 13501 13319 13292 13280 13275>,
			<13844 13543 13322 13292 13280 13275>,
			<13878 13590 13326 13291 13280 13275>,
			<13913 13640 13330 13291 13279 13275>,
			<13947 13696 13334 13292 13278 13274>,
			<13980 13753 13339 13293 13278 13273>,
			<14010 13805 13348 13294 13278 13274>,
			<14035 13852 13361 13295 13278 13275>,
			<14068 13893 13382 13296 13278 13275>,
			<14109 13928 13392 13295 13278 13276>,
			<14135 13922 13373 13292 13278 13275>,
			<14140 13979 13405 13291 13275 13272>,
			<14276 14090 13478 13295 13278 13275>,
			<14414 14153 13542 13297 13282 13279>,
			<14622 14219 13629 13302 13283 13280>,
			<14932 14319 13743 13306 13286 13282>,
			<15460 14526 13908 13311 13288 13283>,
			<16455 15003 14088 13310 13284 13280>,
			<18591 16170 14298 13312 13284 13280>,
			<24426 19806 14887 13323 13286 13283>,
			<51923 37318 16706 13340 13291 13285>,
			<51923 37318 16706 13340 13291 13285>,
			<51923 37318 16706 13340 13291 13285>;
	};

	qcom,pc-temp-y4-lut {
		qcom,lut-col-legend = <(-10) 0 10 25 40 50>;
		qcom,lut-row-legend = <10000 9800 9600 9400 9200 9000>,
			<8800 8600 8400 8200 8000 7800>,
			<7600 7400 7200 7000 6800 6600>,
			<6400 6200 6000 5800 5600 5400>,
			<5200 5000 4800 4600 4400 4200>,
			<4000 3800 3600 3400 3200 3000>,
			<2800 2600 2400 2200 2000 1800>,
			<1600 1400 1200 1000 900 800>,
			<700 600 500 400 300 200>,
			<100 0>;
		qcom,lut-data = <16995 16849 16665 16509 16454 16448>,
			<17152 16916 16705 16509 16454 16446>,
			<17284 17000 16748 16509 16453 16445>,
			<17385 17080 16787 16508 16453 16444>,
			<17446 17137 16814 16508 16452 16443>,
			<17462 17153 16820 16508 16451 16443>,
			<17417 17141 16811 16508 16451 16444>,
			<17367 17124 16800 16507 16451 16444>,
			<17361 17114 16794 16507 16451 16445>,
			<17364 17106 16789 16509 16452 16447>,
			<17362 17104 16789 16510 16454 16447>,
			<17357 17113 16793 16515 16457 16448>,
			<17348 17122 16800 16521 16461 16448>,
			<17311 17133 16817 16528 16467 16451>,
			<17241 17146 16838 16537 16475 16456>,
			<17169 17129 16845 16551 16481 16463>,
			<17086 17049 16850 16570 16487 16471>,
			<17020 16982 16848 16591 16497 16480>,
			<16981 16945 16806 16618 16517 16492>,
			<16946 16913 16755 16635 16536 16504>,
			<16898 16877 16717 16620 16545 16519>,
			<16838 16840 16683 16585 16551 16532>,
			<16785 16802 16658 16550 16540 16521>,
			<16730 16761 16638 16509 16485 16472>,
			<16697 16718 16624 16491 16456 16448>,
			<16695 16661 16613 16488 16455 16447>,
			<16695 16612 16604 16487 16454 16446>,
			<16696 16609 16591 16488 16456 16447>,
			<16700 16620 16574 16492 16461 16451>,
			<16705 16631 16553 16496 16467 16456>,
			<16707 16639 16518 16501 16474 16464>,
			<16710 16646 16500 16506 16482 16473>,
			<16714 16655 16508 16512 16493 16484>,
			<16718 16665 16526 16517 16502 16493>,
			<16723 16675 16546 16515 16503 16493>,
			<16728 16685 16570 16508 16499 16489>,
			<16734 16693 16595 16502 16492 16483>,
			<16741 16698 16622 16497 16474 16467>,
			<16750 16701 16643 16495 16458 16454>,
			<16761 16700 16654 16495 16457 16452>,
			<16776 16692 16659 16496 16457 16451>,
			<16788 16678 16660 16500 16459 16455>,
			<16796 16661 16656 16499 16459 16452>,
			<16779 16639 16610 16480 16452 16447>,
			<16727 16627 16610 16469 16437 16431>,
			<16746 16640 16625 16483 16445 16440>,
			<16781 16654 16640 16495 16451 16447>,
			<16842 16675 16661 16512 16465 16463>,
			<16942 16706 16697 16537 16485 16489>,
			<17054 16769 16746 16565 16503 16503>,
			<17291 16876 16771 16553 16475 16458>,
			<17811 17071 16766 16541 16456 16446>,
			<19566 17956 16916 16565 16462 16450>,
			<32909 27651 17742 16609 16480 16464>,
			<32909 27651 17742 16609 16480 16464>,
			<32909 27651 17742 16609 16480 16464>;
	};

	qcom,pc-temp-y5-lut {
		qcom,lut-col-legend = <(-10) 0 10 25 40 50>;
		qcom,lut-row-legend = <10000 9800 9600 9400 9200 9000>,
			<8800 8600 8400 8200 8000 7800>,
			<7600 7400 7200 7000 6800 6600>,
			<6400 6200 6000 5800 5600 5400>,
			<5200 5000 4800 4600 4400 4200>,
			<4000 3800 3600 3400 3200 3000>,
			<2800 2600 2400 2200 2000 1800>,
			<1600 1400 1200 1000 900 800>,
			<700 600 500 400 300 200>,
			<100 0>;
		qcom,lut-data = <13182 12520 14416 18563 20489 18203>,
			<12886 13136 14829 18691 20122 18443>,
			<12873 13735 15255 18762 19706 18537>,
			<13072 14288 15655 18791 19324 18520>,
			<13416 14765 15994 18787 19058 18429>,
			<13850 15139 16238 18739 18989 18290>,
			<14786 15431 16443 18191 19081 17963>,
			<15580 15669 16572 17511 19169 17600>,
			<15289 15934 16575 17139 19085 17326>,
			<14467 16218 16521 16840 18834 17097>,
			<14246 16227 16449 16507 18518 17327>,
			<14631 15756 16324 16114 18052 18841>,
			<15267 15421 16235 15808 17491 19708>,
			<16631 16234 16261 15529 16622 19150>,
			<18294 17713 16405 15270 15875 18173>,
			<18339 18694 17161 15054 15866 17235>,
			<17072 19519 18952 14721 16036 16233>,
			<16366 19794 20011 14682 16059 15709>,
			<17104 19725 20582 15596 15569 15435>,
			<18367 19656 20850 17022 15165 15314>,
			<19556 19856 20706 19330 16957 16329>,
			<20822 20489 20487 21901 20100 18360>,
			<20938 21370 20551 22146 20625 19836>,
			<17012 23009 21013 21346 20415 21132>,
			<13386 23979 21526 20875 20257 21535>,
			<13146 20207 21994 20574 20070 20681>,
			<13074 14473 22558 20297 19780 19820>,
			<13031 13336 23586 20451 19258 19664>,
			<13062 13112 24863 20953 18505 19472>,
			<13139 13065 24924 21246 18337 18986>,
			<13285 13372 23046 21500 18658 17767>,
			<13457 13807 21307 21852 19132 17090>,
			<13540 14102 20559 23137 19730 17314>,
			<13566 14360 20038 24809 20498 17804>,
			<13558 14595 19750 25070 21459 18603>,
			<13554 14797 19537 25025 22706 19879>,
			<13570 15037 19482 24979 23169 20673>,
			<13568 15479 19181 25016 23047 21071>,
			<13528 15943 18751 24964 22825 21342>,
			<13468 16128 18095 23997 22434 21609>,
			<13374 16219 17266 22374 21798 21785>,
			<13431 15867 16672 21431 21074 21440>,
			<13735 14948 15807 20624 20326 21423>,
			<13916 14248 14760 21622 22333 21372>,
			<14135 14312 14562 20899 21037 21692>,
			<14308 14005 14418 20398 19841 18737>,
			<14137 13972 14610 19538 20939 19583>,
			<13573 14008 14699 19308 18479 18575>,
			<13358 14405 14487 18438 18520 17501>,
			<13039 14375 14548 17986 18171 17112>,
			<12181 13836 14776 18056 18699 19484>,
			<10710 11580 14399 18594 20614 20573>,
			<9503 9967 12364 19416 21898 22617>,
			<8943 9020 10351 19466 24117 25088>,
			<8943 9020 10351 19466 24117 25088>,
			<8943 9020 10351 19466 24117 25088>;
	};

	qcom,pc-temp-y6-lut {
		qcom,lut-col-legend = <(-10) 0 10 25 40 50>;
		qcom,lut-row-legend = <10000 9800 9600 9400 9200 9000>,
			<8800 8600 8400 8200 8000 7800>,
			<7600 7400 7200 7000 6800 6600>,
			<6400 6200 6000 5800 5600 5400>,
			<5200 5000 4800 4600 4400 4200>,
			<4000 3800 3600 3400 3200 3000>,
			<2800 2600 2400 2200 2000 1800>,
			<1600 1400 1200 1000 900 800>,
			<700 600 500 400 300 200>,
			<100 0>;
		qcom,lut-data = <6460 5721 5330 5092 5036 5023>,
			<6438 5748 5349 5094 5036 5023>,
			<6417 5764 5361 5096 5036 5023>,
			<6395 5773 5367 5096 5036 5023>,
			<6373 5776 5369 5097 5036 5023>,
			<6350 5777 5369 5097 5036 5024>,
			<6328 5768 5363 5096 5036 5024>,
			<6305 5756 5356 5095 5037 5025>,
			<6276 5748 5351 5095 5038 5025>,
			<6241 5740 5347 5096 5038 5026>,
			<6218 5732 5344 5096 5039 5027>,
			<6205 5719 5340 5098 5041 5028>,
			<6192 5712 5339 5099 5042 5030>,
			<6178 5712 5340 5102 5044 5032>,
			<6162 5714 5342 5105 5046 5033>,
			<6139 5708 5343 5108 5048 5035>,
			<6101 5686 5342 5113 5051 5037>,
			<6077 5665 5341 5119 5055 5039>,
			<6070 5648 5325 5127 5061 5043>,
			<6065 5634 5305 5132 5065 5047>,
			<6059 5622 5290 5127 5067 5051>,
			<6052 5611 5276 5115 5068 5055>,
			<6043 5604 5267 5102 5064 5051>,
			<6026 5601 5261 5088 5044 5033>,
			<6015 5596 5257 5081 5034 5024>,
			<6023 5586 5255 5080 5033 5023>,
			<6047 5575 5254 5079 5033 5023>,
			<6072 5580 5252 5080 5033 5023>,
			<6100 5609 5250 5082 5034 5024>,
			<6129 5644 5248 5083 5036 5026>,
			<6159 5682 5244 5086 5038 5028>,
			<6190 5725 5241 5088 5041 5030>,
			<6220 5769 5251 5091 5045 5033>,
			<6249 5815 5270 5093 5048 5036>,
			<6277 5861 5291 5093 5049 5036>,
			<6305 5908 5317 5091 5048 5035>,
			<6333 5955 5345 5091 5046 5034>,
			<6360 6004 5376 5092 5040 5028>,
			<6386 6052 5409 5093 5035 5025>,
			<6414 6095 5440 5095 5035 5025>,
			<6442 6133 5471 5097 5035 5025>,
			<6475 6164 5507 5102 5037 5027>,
			<6510 6191 5536 5103 5037 5026>,
			<6534 6190 5497 5095 5035 5024>,
			<6543 6234 5565 5094 5029 5018>,
			<6660 6324 5674 5105 5034 5023>,
			<6798 6378 5749 5112 5039 5028>,
			<7006 6443 5840 5123 5043 5034>,
			<7316 6530 5956 5136 5052 5043>,
			<7794 6726 6111 5151 5058 5047>,
			<8670 7156 6272 5151 5048 5033>,
			<10465 8133 6448 5158 5042 5029>,
			<15169 11054 6991 5193 5047 5033>,
			<35207 25375 8571 5250 5057 5040>,
			<35207 25375 8571 5250 5057 5040>,
			<35207 25375 8571 5250 5057 5040>;
	};
};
